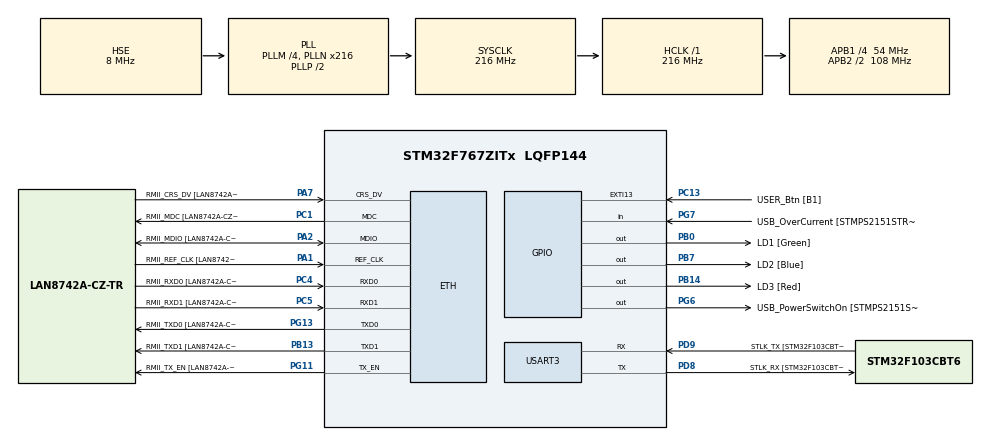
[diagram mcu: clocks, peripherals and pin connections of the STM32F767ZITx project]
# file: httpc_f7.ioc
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Mcu.Family=STM32F7
RCC.CortexFreq_Value=216000000
PG6.Signal=GPIO_Output
PB14.GPIO_Label=LD3 [Red]
PG6.GPIO_Label=USB_PowerSwitchOn [STMPS2151STR_EN]
PA14.GPIO_Label=TCK
RCC.SYSCLKSourceVirtual=RCC_SYSCLKSOURCE_PLLCLK
CORTEX_M7.PREFETCH_ENABLE=0
PB0.GPIO_Label=LD1 [Green]
PC14/OSC32_IN.Mode=LSE-External-Oscillator
PC5.Mode=RMII
PC13.GPIO_Label=USER_Btn [B1]
PB13.GPIO_Label=RMII_TXD1 [LAN8742A-CZ-TR_TXD1]
PB13.Signal=ETH_TXD1
PG13.Signal=ETH_TXD0
PD9.Mode=Asynchronous
PG11.Signal=ETH_TX_EN
RCC.SYSCLKSource=RCC_SYSCLKSOURCE_PLLCLK
ProjectManager.StackSize=0x400
LWIP.LWIP_HTTPD=1
USART3.VirtualMode-Asynchronous=VM_ASYNC
PA12.Signal=USB_OTG_FS_DP
ETH.PHY_Value=0
PH0/OSC_IN.Mode=HSE-External-Clock-Source
RCC.HCLKFreq_Value=216000000
RCC.APB2TimFreq_Value=216000000
PH1/OSC_OUT.Signal=RCC_OSC_OUT
PD8.Signal=USART3_TX
RCC.AHBFreq_Value=216000000
NVIC.ETH_IRQn=true\:5\:0\:false\:false\:true\:true\:false\:true
RCC.HSE_VALUE=8000000
RCC.PLLMUL=RCC_PLL_MUL9
PC4.GPIO_Label=RMII_RXD0 [LAN8742A-CZ-TR_RXD0]
PA14.Mode=Serial_Wire
NVIC.TIM2_IRQn=true\:5\:0\:false\:false\:true\:true\:true\:true
PA10.GPIO_Label=USB_ID
PB7.Signal=GPIO_Output
PA8.Signal=USB_OTG_FS_SOF
PG13.Mode=RMII
ETH.PHY_Name=LAN8742A_PHY_ADDRESS
VP_FREERTOS_VS_CMSIS_V1.Mode=CMSIS_V1
PH1/OSC_OUT.Mode=HSE-External-Clock-Source
PB7.GPIO_Label=LD2 [Blue]
Mcu.Package=LQFP144
NVIC.TimeBase=TIM3_IRQn
PC14/OSC32_IN.Signal=RCC_OSC32_IN
PA2.GPIO_Label=RMII_MDIO [LAN8742A-CZ-TR_MDIO]
NVIC.TimeBaseIP=TIM3
PA10.Signal=USB_OTG_FS_ID
RCC.APB2CLKDivider=RCC_HCLK_DIV2
RCC.APB1TimFreq_Value=108000000
PG11.GPIO_Label=RMII_TX_EN [LAN8742A-CZ-TR_TXEN]
PC5.Signal=ETH_RXD1
PB13.Mode=RMII
PC4.Mode=RMII
PB3.GPIO_Label=SWO
RCC.PLLSourceVirtual=RCC_PLLSOURCE_HSE
CORTEX_M7.CPU_ICache=Enabled
FREERTOS.Tasks01=defaultTask,0,128,StartDefaultTask,Default,NULL,Dynamic,NULL,NULL
PA7.Mode=RMII
PG7.Signal=GPIO_Input
PD9.GPIO_Label=STLK_TX [STM32F103CBT6_PA2]
PC13.Signal=GPXTI13
PA9.GPIO_Label=USB_VBUS
PC4.Signal=ETH_RXD0
PA11.GPIO_Label=USB_DM
PD9.Signal=USART3_RX
LWIP.LWIP_DHCP=0
RCC.APB1CLKDivider=RCC_HCLK_DIV4
PG13.GPIO_Label=RMII_TXD0 [LAN8742A-CZ-TR_TXD0]
ETH.PhyAddress=0
PA12.GPIO_Label=USB_DP
VP_LWIP_VS_Enabled.Mode=Enabled
LWIP.LWIP_DNS=1
PD8.GPIO_Label=STLK_RX [STM32F103CBT6_PA3]
PA13.Signal=SYS_JTMS-SWDIO
CORTEX_M7.MPU_Control=MPU_HFNMI_PRIVDEF
VP_SYS_VS_tim3.Mode=TIM3
PA8.GPIO_Label=USB_SOF [TP1]
ProjectManager.TargetToolchain=TrueSTUDIO
LWIP.LWIP_SNTP=0
PA9.Signal=USB_OTG_FS_VBUS
RCC.USBFreq_Value=48000000
PD8.Mode=Asynchronous
PA1.Signal=ETH_REF_CLK
PB14.Signal=GPIO_Output
board=NUCLEO-F767ZI
RCC.VCOOutputFreq_Value=432000000
NVIC.TIM3_IRQn=true\:0\:0\:false\:false\:true\:false\:false\:true
PH0/OSC_IN.Signal=RCC_OSC_IN
RCC.APB2Freq_Value=108000000
PA1.Mode=RMII
LWIP.MEMP_NUM_TCP_PCB=8
RCC.PRESCALERUSB=RCC_USBCLKSOURCE_PLL_DIV1_5
VP_TIM2_VS_ClockSourceINT.Mode=Internal
PG7.GPIO_Label=USB_OverCurrent [STMPS2151STR_FAULT]
PA1.GPIO_Label=RMII_REF_CLK [LAN8742A-CZ-TR_REFCLK0]
PC1.GPIO_Label=RMII_MDC [LAN8742A-CZ-TR_MDC]
PA13.Mode=Serial_Wire
Mcu.Name=STM32F767ZITx
PA2.Signal=ETH_MDIO
PA13.GPIO_Label=TMS
RCC.48MHZClocksFreq_Value=24000000
PB3.Signal=SYS_JTDO-SWO
RCC.SYSCLKFreq_VALUE=216000000
ETH.MediaInterface=ETH_MEDIA_INTERFACE_RMII
PA7.GPIO_Label=RMII_CRS_DV [LAN8742A-CZ-TR_CRS_DV]
PC5.GPIO_Label=RMII_RXD1 [LAN8742A-CZ-TR_RXD1]
PC15/OSC32_OUT.Mode=LSE-External-Oscillator
PG11.Mode=RMII
PA11.Signal=USB_OTG_FS_DM
PA14.Signal=SYS_JTCK-SWCLK
ProjectManager.HeapSize=0x200
LWIP.Version=v2.1.2_Cube
RCC.HSI_VALUE=16000000
PH0/OSC_IN.GPIO_Label=MCO [STM32F103CBT6_PA8]
VP_TIM4_VS_ClockSourceINT.Mode=Internal
RCC.PLLQ=9
NVIC.PriorityGroup=NVIC_PRIORITYGROUP_4
RCC.PLLM=4
RCC.PLLN=216
PA2.Mode=RMII
PC15/OSC32_OUT.Signal=RCC_OSC32_OUT
CORTEX_M7.CPU_DCache=Enabled
NVIC.TIM4_IRQn=true\:5\:0\:false\:false\:true\:true\:true\:true
RCC.APB1Freq_Value=54000000
PB0.Signal=GPIO_Output
PC1.Signal=ETH_MDC
PC1.Mode=RMII
PA7.Signal=ETH_CRS_DV

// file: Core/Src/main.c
/* USER CODE BEGIN Header */
/**
  ******************************************************************************
  * @file           : main.c
  * @brief          : Main program body
  ******************************************************************************
  * @attention
  *
  * <h2><center>&copy; Copyright (c) 2021 STMicroelectronics.
  * All rights reserved.</center></h2>
  *
  * This software component is licensed by ST under Ultimate Liberty license
  * SLA0044, the "License"; You may not use this file except in compliance with
  * the License. You may obtain a copy of the License at:
  *                             www.st.com/SLA0044
  *
  ******************************************************************************
  */
/* USER CODE END Header */
#include "main.h"
#include "cmsis_os.h"
#include "lwip.h"

TIM_HandleTypeDef htim2;
TIM_HandleTypeDef htim4;

UART_HandleTypeDef huart3;

osThreadId defaultTaskHandle;

void SystemClock_Config(void);
static void MPU_Config(void);
static void MX_GPIO_Init(void);
static void MX_TIM2_Init(void);
static void MX_TIM4_Init(void);
static void MX_USART3_UART_Init(void);
void StartDefaultTask(void const * argument);

/* USER CODE BEGIN 0 */

#if (defined(__GNUC__) && !defined(__CC_ARM))
/* With GCC/RAISONANCE, small printf (option LD Linker->Libraries->Small printf
   set to 'Yes') calls __io_putchar() */
#define PUTCHAR_PROTOTYPE int __io_putchar(int ch)
#define GETCHAR_PROTOTYPE int __io_getchar(void)
#else
#define PUTCHAR_PROTOTYPE int fputc(int ch, FILE *f)
#define GETCHAR_PROTOTYPE int fgetc(FILE *f)
#endif /* __GNUC__ */

/**
  * @brief  Retargets the C library printf function to the USART.
  * @param  None
  * @retval None
  */
PUTCHAR_PROTOTYPE
{
  /* Place your implementation of fputc here */
  /* e.g. write a character to the USART2 and Loop until the end of transmission */
  while (HAL_OK != HAL_UART_Transmit(&huart3, (uint8_t *) &ch, 1, 30000))
  {
    ;
  }
  return ch;
}

/* USER CODE END 0 */

int main(void)
{

  /* MPU Configuration--------------------------------------------------------*/
  MPU_Config();

  /* Enable I-Cache---------------------------------------------------------*/
  SCB_EnableICache();

  /* Enable D-Cache---------------------------------------------------------*/
  SCB_EnableDCache();

  /* MCU Configuration--------------------------------------------------------*/

  /* Reset of all peripherals, Initializes the Flash interface and the Systick. */
  HAL_Init();

  /* Configure the system clock */
  SystemClock_Config();

  /* Initialize all configured peripherals */
  MX_GPIO_Init();
  MX_TIM2_Init();
  MX_TIM4_Init();
  MX_USART3_UART_Init();

  /* Create the thread(s) */
  /* definition and creation of defaultTask */
  osThreadDef(defaultTask, StartDefaultTask, osPriorityNormal, 0, 1024*5);
  defaultTaskHandle = osThreadCreate(osThread(defaultTask), NULL);

  /* Start scheduler */
  osKernelStart();

  /* We should never get here as control is now taken by the scheduler */
  /* Infinite loop */
  while (1)
  {

  }
}

void SystemClock_Config(void)
{
  RCC_OscInitTypeDef RCC_OscInitStruct = {0};
  RCC_ClkInitTypeDef RCC_ClkInitStruct = {0};
  RCC_PeriphCLKInitTypeDef PeriphClkInitStruct = {0};

  /** Configure LSE Drive Capability
  */
  HAL_PWR_EnableBkUpAccess();
  /** Configure the main internal regulator output voltage
  */
  __HAL_RCC_PWR_CLK_ENABLE();
  __HAL_PWR_VOLTAGESCALING_CONFIG(PWR_REGULATOR_VOLTAGE_SCALE1);
  /** Initializes the RCC Oscillators according to the specified parameters
  * in the RCC_OscInitTypeDef structure.
  */
  RCC_OscInitStruct.OscillatorType = RCC_OSCILLATORTYPE_HSE;
  RCC_OscInitStruct.HSEState = RCC_HSE_BYPASS;
  RCC_OscInitStruct.PLL.PLLState = RCC_PLL_ON;
  RCC_OscInitStruct.PLL.PLLSource = RCC_PLLSOURCE_HSE;
  RCC_OscInitStruct.PLL.PLLM = 4;
  RCC_OscInitStruct.PLL.PLLN = 216;
  RCC_OscInitStruct.PLL.PLLP = RCC_PLLP_DIV2;
  RCC_OscInitStruct.PLL.PLLQ = 9;
  if (HAL_RCC_OscConfig(&RCC_OscInitStruct) != HAL_OK)
  {
    Error_Handler();
  }
  /** Activate the Over-Drive mode
  */
  if (HAL_PWREx_EnableOverDrive() != HAL_OK)
  {
    Error_Handler();
  }
  /** Initializes the CPU, AHB and APB buses clocks
  */
  RCC_ClkInitStruct.ClockType = RCC_CLOCKTYPE_HCLK|RCC_CLOCKTYPE_SYSCLK
                              |RCC_CLOCKTYPE_PCLK1|RCC_CLOCKTYPE_PCLK2;
  RCC_ClkInitStruct.SYSCLKSource = RCC_SYSCLKSOURCE_PLLCLK;
  RCC_ClkInitStruct.AHBCLKDivider = RCC_SYSCLK_DIV1;
  RCC_ClkInitStruct.APB1CLKDivider = RCC_HCLK_DIV4;
  RCC_ClkInitStruct.APB2CLKDivider = RCC_HCLK_DIV2;

  if (HAL_RCC_ClockConfig(&RCC_ClkInitStruct, FLASH_LATENCY_7) != HAL_OK)
  {
    Error_Handler();
  }
  PeriphClkInitStruct.PeriphClockSelection = RCC_PERIPHCLK_USART3;
  PeriphClkInitStruct.Usart3ClockSelection = RCC_USART3CLKSOURCE_PCLK1;
  if (HAL_RCCEx_PeriphCLKConfig(&PeriphClkInitStruct) != HAL_OK)
  {
    Error_Handler();
  }
}

static void MX_TIM2_Init(void)
{

  TIM_ClockConfigTypeDef sClockSourceConfig = {0};
  TIM_MasterConfigTypeDef sMasterConfig = {0};

  htim2.Instance = TIM2;
  htim2.Init.Prescaler = 0;
  htim2.Init.CounterMode = TIM_COUNTERMODE_UP;
  htim2.Init.Period = 0xffff;
  htim2.Init.ClockDivision = TIM_CLOCKDIVISION_DIV1;
  htim2.Init.AutoReloadPreload = TIM_AUTORELOAD_PRELOAD_DISABLE;
  if (HAL_TIM_Base_Init(&htim2) != HAL_OK)
  {
    Error_Handler();
  }
  sClockSourceConfig.ClockSource = TIM_CLOCKSOURCE_INTERNAL;
  if (HAL_TIM_ConfigClockSource(&htim2, &sClockSourceConfig) != HAL_OK)
  {
    Error_Handler();
  }
  sMasterConfig.MasterOutputTrigger = TIM_TRGO_RESET;
  sMasterConfig.MasterSlaveMode = TIM_MASTERSLAVEMODE_DISABLE;
  if (HAL_TIMEx_MasterConfigSynchronization(&htim2, &sMasterConfig) != HAL_OK)
  {
    Error_Handler();
  }

}

static void MX_TIM4_Init(void)
{

  TIM_ClockConfigTypeDef sClockSourceConfig = {0};
  TIM_MasterConfigTypeDef sMasterConfig = {0};

  htim4.Instance = TIM4;
  htim4.Init.Prescaler = 0;
  htim4.Init.CounterMode = TIM_COUNTERMODE_UP;
  htim4.Init.Period = 0xffff;
  htim4.Init.ClockDivision = TIM_CLOCKDIVISION_DIV1;
  htim4.Init.AutoReloadPreload = TIM_AUTORELOAD_PRELOAD_DISABLE;
  if (HAL_TIM_Base_Init(&htim4) != HAL_OK)
  {
    Error_Handler();
  }
  sClockSourceConfig.ClockSource = TIM_CLOCKSOURCE_INTERNAL;
  if (HAL_TIM_ConfigClockSource(&htim4, &sClockSourceConfig) != HAL_OK)
  {
    Error_Handler();
  }
  sMasterConfig.MasterOutputTrigger = TIM_TRGO_RESET;
  sMasterConfig.MasterSlaveMode = TIM_MASTERSLAVEMODE_DISABLE;
  if (HAL_TIMEx_MasterConfigSynchronization(&htim4, &sMasterConfig) != HAL_OK)
  {
    Error_Handler();
  }

}

static void MX_USART3_UART_Init(void)
{

  huart3.Instance = USART3;
  huart3.Init.BaudRate = 115200;
  huart3.Init.WordLength = UART_WORDLENGTH_8B;
  huart3.Init.StopBits = UART_STOPBITS_1;
  huart3.Init.Parity = UART_PARITY_NONE;
  huart3.Init.Mode = UART_MODE_TX_RX;
  huart3.Init.HwFlowCtl = UART_HWCONTROL_NONE;
  huart3.Init.OverSampling = UART_OVERSAMPLING_16;
  huart3.Init.OneBitSampling = UART_ONE_BIT_SAMPLE_DISABLE;
  huart3.AdvancedInit.AdvFeatureInit = UART_ADVFEATURE_NO_INIT;
  if (HAL_UART_Init(&huart3) != HAL_OK)
  {
    Error_Handler();
  }

}

static void MX_GPIO_Init(void)
{
  GPIO_InitTypeDef GPIO_InitStruct = {0};

  /* GPIO Ports Clock Enable */
  __HAL_RCC_GPIOC_CLK_ENABLE();
  __HAL_RCC_GPIOH_CLK_ENABLE();
  __HAL_RCC_GPIOA_CLK_ENABLE();
  __HAL_RCC_GPIOB_CLK_ENABLE();
  __HAL_RCC_GPIOD_CLK_ENABLE();
  __HAL_RCC_GPIOG_CLK_ENABLE();

  /*Configure GPIO pin Output Level */
  HAL_GPIO_WritePin(GPIOB, LD1_Pin|LD3_Pin|LD2_Pin, GPIO_PIN_RESET);

  /*Configure GPIO pin Output Level */
  HAL_GPIO_WritePin(USB_PowerSwitchOn_GPIO_Port, USB_PowerSwitchOn_Pin, GPIO_PIN_RESET);

  /*Configure GPIO pin : USER_Btn_Pin */
  GPIO_InitStruct.Pin = USER_Btn_Pin;
  GPIO_InitStruct.Mode = GPIO_MODE_IT_RISING;
  GPIO_InitStruct.Pull = GPIO_NOPULL;
  HAL_GPIO_Init(USER_Btn_GPIO_Port, &GPIO_InitStruct);

  /*Configure GPIO pins : LD1_Pin LD3_Pin LD2_Pin */
  GPIO_InitStruct.Pin = LD1_Pin|LD3_Pin|LD2_Pin;
  GPIO_InitStruct.Mode = GPIO_MODE_OUTPUT_PP;
  GPIO_InitStruct.Pull = GPIO_NOPULL;
  GPIO_InitStruct.Speed = GPIO_SPEED_FREQ_LOW;
  HAL_GPIO_Init(GPIOB, &GPIO_InitStruct);

  /*Configure GPIO pin : USB_PowerSwitchOn_Pin */
  GPIO_InitStruct.Pin = USB_PowerSwitchOn_Pin;
  GPIO_InitStruct.Mode = GPIO_MODE_OUTPUT_PP;
  GPIO_InitStruct.Pull = GPIO_NOPULL;
  GPIO_InitStruct.Speed = GPIO_SPEED_FREQ_LOW;
  HAL_GPIO_Init(USB_PowerSwitchOn_GPIO_Port, &GPIO_InitStruct);

  /*Configure GPIO pin : USB_OverCurrent_Pin */
  GPIO_InitStruct.Pin = USB_OverCurrent_Pin;
  GPIO_InitStruct.Mode = GPIO_MODE_INPUT;
  GPIO_InitStruct.Pull = GPIO_NOPULL;
  HAL_GPIO_Init(USB_OverCurrent_GPIO_Port, &GPIO_InitStruct);

  /*Configure GPIO pins : USB_SOF_Pin USB_ID_Pin USB_DM_Pin USB_DP_Pin */
  GPIO_InitStruct.Pin = USB_SOF_Pin|USB_ID_Pin|USB_DM_Pin|USB_DP_Pin;
  GPIO_InitStruct.Mode = GPIO_MODE_AF_PP;
  GPIO_InitStruct.Pull = GPIO_NOPULL;
  GPIO_InitStruct.Speed = GPIO_SPEED_FREQ_VERY_HIGH;
  GPIO_InitStruct.Alternate = GPIO_AF10_OTG_FS;
  HAL_GPIO_Init(GPIOA, &GPIO_InitStruct);

  /*Configure GPIO pin : USB_VBUS_Pin */
  GPIO_InitStruct.Pin = USB_VBUS_Pin;
  GPIO_InitStruct.Mode = GPIO_MODE_INPUT;
  GPIO_InitStruct.Pull = GPIO_NOPULL;
  HAL_GPIO_Init(USB_VBUS_GPIO_Port, &GPIO_InitStruct);

}

void StartDefaultTask(void const * argument)
{
  /* init code for LWIP */
  MX_LWIP_Init();
  /* USER CODE BEGIN 5 */
  httpd_init();
  /* Infinite loop */
  for(;;)
  {
    osDelay(1);
  }
  /* USER CODE END 5 */
}

/* MPU Configuration */

void MPU_Config(void)
{

	MPU_Region_InitTypeDef MPU_InitStruct;
	/* Disable the MPU */
	HAL_MPU_Disable();
	/* Configure the MPU as Normal Non Cacheable for Ethernet Buffers in the SRAM2 */
	MPU_InitStruct.Enable = MPU_REGION_ENABLE;
	MPU_InitStruct.BaseAddress = 0x2007C000;
	MPU_InitStruct.Size = MPU_REGION_SIZE_16KB;
	MPU_InitStruct.AccessPermission = MPU_REGION_FULL_ACCESS;
	MPU_InitStruct.IsBufferable = MPU_ACCESS_NOT_BUFFERABLE;
	MPU_InitStruct.IsCacheable = MPU_ACCESS_NOT_CACHEABLE;
	MPU_InitStruct.IsShareable = MPU_ACCESS_SHAREABLE;
	MPU_InitStruct.Number = MPU_REGION_NUMBER0;
	MPU_InitStruct.TypeExtField = MPU_TEX_LEVEL1;
	MPU_InitStruct.SubRegionDisable = 0x00;
	MPU_InitStruct.DisableExec = MPU_INSTRUCTION_ACCESS_ENABLE;
	HAL_MPU_ConfigRegion(&MPU_InitStruct);
	/* Configure the MPU as Device for Ethernet Descriptors in the SRAM2 */
	MPU_InitStruct.Enable = MPU_REGION_ENABLE;
	MPU_InitStruct.BaseAddress = 0x2007C000;
	MPU_InitStruct.Size = MPU_REGION_SIZE_256B;
	MPU_InitStruct.AccessPermission = MPU_REGION_FULL_ACCESS;
	MPU_InitStruct.IsBufferable = MPU_ACCESS_BUFFERABLE;
	MPU_InitStruct.IsCacheable = MPU_ACCESS_NOT_CACHEABLE;
	MPU_InitStruct.IsShareable = MPU_ACCESS_SHAREABLE;
	MPU_InitStruct.Number = MPU_REGION_NUMBER1;
	MPU_InitStruct.TypeExtField = MPU_TEX_LEVEL0;
	MPU_InitStruct.SubRegionDisable = 0x00;
	MPU_InitStruct.DisableExec = MPU_INSTRUCTION_ACCESS_ENABLE;
	HAL_MPU_ConfigRegion(&MPU_InitStruct);

		  /* Enable the MPU */
		  HAL_MPU_Enable(MPU_PRIVILEGED_DEFAULT);

}
void HAL_TIM_PeriodElapsedCallback(TIM_HandleTypeDef *htim)
{
  if (htim->Instance == TIM3) {
    HAL_IncTick();
  }
}

void Error_Handler(void)
{
  __disable_irq();
  while (1)
  {
  }
}

/************************ (C) COPYRIGHT STMicroelectronics *****END OF FILE****/
